VERSION "0.0.0"

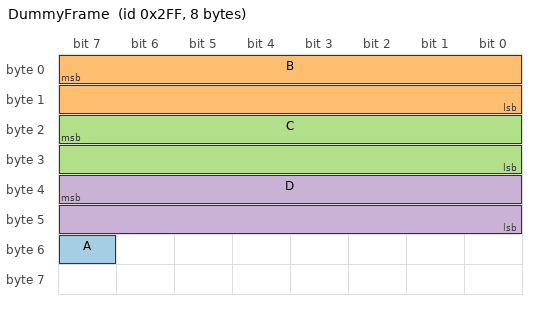
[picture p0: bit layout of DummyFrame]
BO_ 767 DummyFrame: 8 ECUA
 SG_ A : 55|1@0+ (1,0) [0|1] "" ECUB
 SG_ B : 7|16@0+ (1.0, 0.0) [0.0|65535.0] "NoUnit" ECUB
 SG_ C : 23|16@0+ (1.0, 0.0) [0.0|65535.0] "NoUnit" ECUB
 SG_ D : 39|16@0+ (1.0, 0.0) [0.0|65535.0] "NoUnit" ECUB

BA_DEF_ BO_ "GenMsgCycleTime" FLOAT 0 300000;

BA_ "GenMsgCycleTime" BO_ 767 200;

VAL_ 767 B 2 "Fast" 1 "Slow" 0 "Off";
